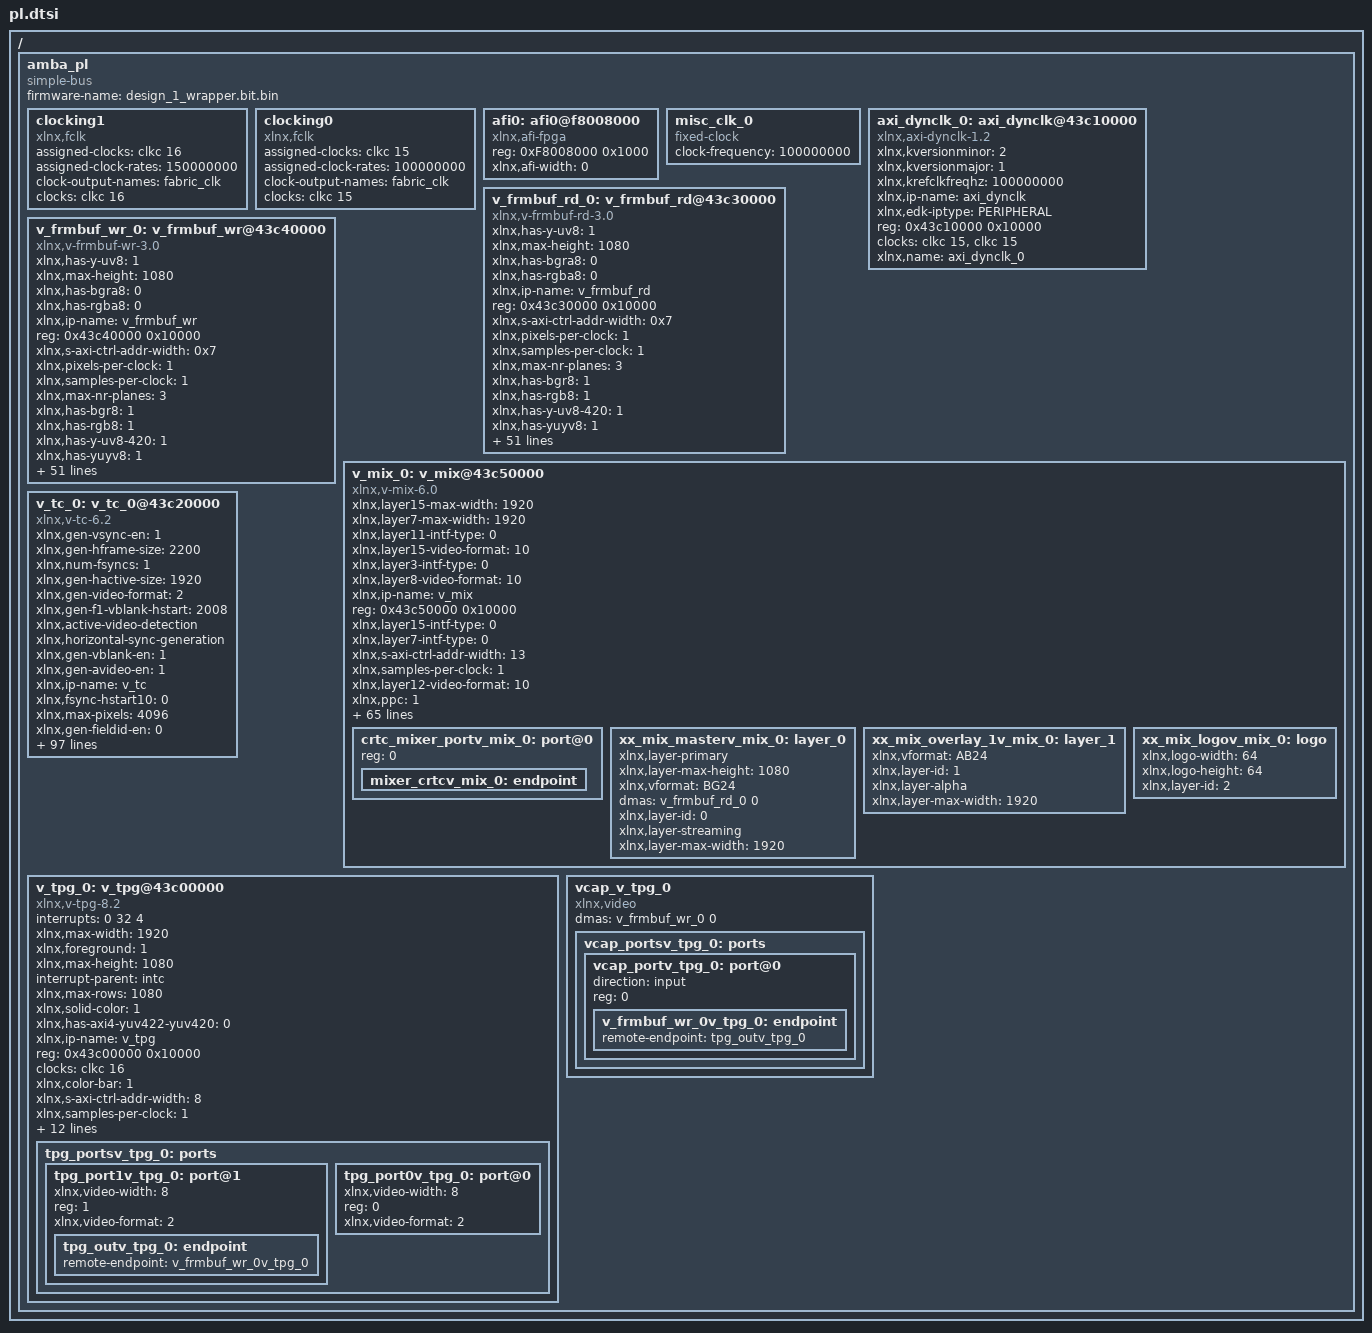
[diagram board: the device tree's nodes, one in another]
/ {
	amba_pl: amba_pl {
		ranges;
		compatible = "simple-bus";
		#address-cells = <1>;
		#size-cells = <1>;
		firmware-name = "design_1_wrapper.bit.bin";
		clocking1: clocking1 {
			compatible = "xlnx,fclk";
			assigned-clocks = <&clkc 16>;
			assigned-clock-rates = <150000000>;
			#clock-cells = <0>;
			clock-output-names = "fabric_clk";
			clocks = <&clkc 16>;
		};
		clocking0: clocking0 {
			compatible = "xlnx,fclk";
			assigned-clocks = <&clkc 15>;
			assigned-clock-rates = <100000000>;
			#clock-cells = <0>;
			clock-output-names = "fabric_clk";
			clocks = <&clkc 15>;
		};
		afi0: afi0@f8008000 {
			status = "okay";
			compatible = "xlnx,afi-fpga";
			#address-cells = <1>;
			reg = <0xF8008000 0x1000>;
			#size-cells = <0>;
			xlnx,afi-width = <0>;
		};
		misc_clk_0: misc_clk_0 {
			compatible = "fixed-clock";
			clock-frequency = <100000000>;
			#clock-cells = <0>;
		};
		axi_dynclk_0: axi_dynclk@43c10000 {
			xlnx,kversionminor = <2>;
			xlnx,kversionmajor = <1>;
			xlnx,krefclkfreqhz = <100000000>;
			compatible = "xlnx,axi-dynclk-1.2";
			status = "okay";
			clock-names = "REF_CLK_I" , "s_axi_lite_aclk";
			xlnx,ip-name = "axi_dynclk";
			xlnx,edk-iptype = "PERIPHERAL";
			reg = <0x43c10000 0x10000>;
			clocks = <&clkc 15>, <&clkc 15>;
			xlnx,name = "axi_dynclk_0";
		};
		v_frmbuf_rd_0: v_frmbuf_rd@43c30000 {
			xlnx,has-y-uv8 = <1>;
			xlnx,max-height = <1080>;
			xlnx,has-bgra8 = <0>;
			xlnx,has-rgba8 = <0>;
			xlnx,ip-name = "v_frmbuf_rd";
			reg = <0x43c30000 0x10000>;
			xlnx,s-axi-ctrl-addr-width = <0x7>;
			xlnx,pixels-per-clock = <1>;
			xlnx,samples-per-clock = <1>;
			xlnx,max-nr-planes = <3>;
			xlnx,has-bgr8 = <1>;
			xlnx,has-rgb8 = <1>;
			xlnx,has-y-uv8-420 = <1>;
			xlnx,has-yuyv8 = <1>;
			xlnx,has-y-u-v8 = <1>;
			interrupt-names = "interrupt";
			compatible = "xlnx,v-frmbuf-rd-3.0" , "xlnx,axi-frmbuf-rd-v2.2";
			xlnx,max-width = <1920>;
			xlnx,has-rgb16 = <0>;
			xlnx,vid-formats = "rgb888" , "xbgr8888" , "xrgb8888" , "bgr888" , "uyvy" , "y8" , "vuy888" , "xvuy8888" , "yuyv" , "nv12" , "nv16" , "y_u_v8";
			xlnx,has-bgrx8 = <1>;
			xlnx,has-rgbx8 = <1>;
			xlnx,has-rgbx10 = <0>;
			interrupt-parent = <&intc>;
			xlnx,aximm-num-outstanding = <4>;
			xlnx,has-uyvy8 = <1>;
			xlnx,use-uram = <0>;
			xlnx,has-rgbx12 = <0>;
			xlnx,aximm-burst-length = <16>;
			xlnx,aximm-addr-width = <32>;
			xlnx,video-width = <8>;
			xlnx,max-cols = <1920>;
			xlnx,has-yuv8 = <1>;
			status = "okay";
			xlnx,has-y-uv10-420 = <0>;
			xlnx,has-yuva8 = <0>;
			xlnx,has-y-uv12-420 = <0>;
			xlnx,name = "v_frmbuf_rd_0";
			interrupts = < 0 30 4 >;
			xlnx,has-y10 = <0>;
			xlnx,has-y-uv16-420 = <0>;
			xlnx,has-y12 = <0>;
			xlnx,has-alpha = <0>;
			xlnx,has-y-u-v10 = <0>;
			clocks = <&clkc 16>;
			xlnx,has-y16 = <0>;
			xlnx,dma-align = <8>;
			xlnx,has-y-u-v12 = <0>;
			xlnx,edk-iptype = "PERIPHERAL";
			xlnx,has-interlaced = <0>;
			xlnx,has-yuv16 = <0>;
			xlnx,has-yuvx8 = <1>;
			xlnx,is-tile-format = <0>;
			xlnx,dma-addr-width = <32>;
			clock-names = "ap_clk";
			xlnx,s-axi-ctrl-data-width = <0x20>;
			xlnx,has-y8 = <1>;
			xlnx,has-y-uv10 = <0>;
			xlnx,has-y-uv12 = <0>;
			xlnx,max-rows = <1080>;
			xlnx,has-yuvx10 = <0>;
			#dma-cells = <1>;
			xlnx,has-yuvx12 = <0>;
			xlnx,has-y-uv16 = <0>;
			xlnx,max-data-width = <8>;
			xlnx,has-y-u-v8-420 = <1>;
			xlnx,num-video-components = <3>;
			xlnx,aximm-data-width = <64>;
		};
		v_frmbuf_wr_0: v_frmbuf_wr@43c40000 {
			xlnx,has-y-uv8 = <1>;
			xlnx,max-height = <1080>;
			xlnx,has-bgra8 = <0>;
			xlnx,has-rgba8 = <0>;
			xlnx,ip-name = "v_frmbuf_wr";
			reg = <0x43c40000 0x10000>;
			xlnx,s-axi-ctrl-addr-width = <0x7>;
			xlnx,pixels-per-clock = <1>;
			xlnx,samples-per-clock = <1>;
			xlnx,max-nr-planes = <3>;
			xlnx,has-bgr8 = <1>;
			xlnx,has-rgb8 = <1>;
			xlnx,has-y-uv8-420 = <1>;
			xlnx,has-yuyv8 = <1>;
			xlnx,has-y-u-v8 = <1>;
			interrupt-names = "interrupt";
			compatible = "xlnx,v-frmbuf-wr-3.0" , "xlnx,axi-frmbuf-wr-v2.2";
			xlnx,max-width = <1920>;
			xlnx,has-rgb16 = <0>;
			xlnx,vid-formats = "rgb888" , "bgr888" , "xbgr8888" , "xrgb8888" , "uyvy" , "y8" , "vuy888" , "xvuy8888" , "yuyv" , "nv12" , "nv16" , "y_u_v8";
			xlnx,has-bgrx8 = <1>;
			xlnx,has-rgbx8 = <1>;
			xlnx,has-rgbx10 = <0>;
			interrupt-parent = <&intc>;
			xlnx,aximm-num-outstanding = <4>;
			xlnx,has-uyvy8 = <1>;
			xlnx,use-uram = <0>;
			xlnx,has-rgbx12 = <0>;
			xlnx,aximm-burst-length = <16>;
			xlnx,aximm-addr-width = <32>;
			xlnx,video-width = <8>;
			xlnx,max-cols = <1920>;
			xlnx,has-yuv8 = <1>;
			status = "okay";
			xlnx,has-y-uv10-420 = <0>;
			xlnx,has-yuva8 = <0>;
			xlnx,has-y-uv12-420 = <0>;
			xlnx,name = "v_frmbuf_wr_0";
			interrupts = < 0 31 4 >;
			xlnx,has-y10 = <0>;
			xlnx,has-y-uv16-420 = <0>;
			xlnx,has-y12 = <0>;
			xlnx,has-alpha = <0>;
			xlnx,has-y-u-v10 = <0>;
			clocks = <&clkc 16>;
			xlnx,has-y16 = <0>;
			xlnx,dma-align = <8>;
			xlnx,has-y-u-v12 = <0>;
			xlnx,edk-iptype = "PERIPHERAL";
			xlnx,has-interlaced = <0>;
			xlnx,has-yuv16 = <0>;
			xlnx,has-yuvx8 = <1>;
			xlnx,is-tile-format = <0>;
			xlnx,dma-addr-width = <32>;
			clock-names = "ap_clk";
			xlnx,s-axi-ctrl-data-width = <0x20>;
			xlnx,has-y8 = <1>;
			xlnx,has-y-uv10 = <0>;
			xlnx,has-y-uv12 = <0>;
			xlnx,max-rows = <1080>;
			xlnx,has-yuvx10 = <0>;
			#dma-cells = <1>;
			xlnx,has-yuvx12 = <0>;
			xlnx,has-y-uv16 = <0>;
			xlnx,max-data-width = <8>;
			xlnx,has-y-u-v8-420 = <1>;
			xlnx,num-video-components = <3>;
			xlnx,aximm-data-width = <64>;
		};
		v_mix_0: v_mix@43c50000 {
			xlnx,layer15-max-width = <1920>;
			xlnx,layer7-max-width = <1920>;
			xlnx,layer11-intf-type = <0>;
			xlnx,layer15-video-format = <10>;
			xlnx,layer3-intf-type = <0>;
			xlnx,layer8-video-format = <10>;
			xlnx,ip-name = "v_mix";
			reg = <0x43c50000 0x10000>;
			xlnx,layer15-intf-type = <0>;
			xlnx,layer7-intf-type = <0>;
			xlnx,s-axi-ctrl-addr-width = <13>;
			xlnx,samples-per-clock = <1>;
			xlnx,layer12-video-format = <10>;
			xlnx,ppc = <1>;
			xlnx,max-logo-rows = <64>;
			xlnx,layer5-video-format = <10>;
			interrupt-names = "interrupt";
			xlnx,layer12-max-width = <1920>;
			xlnx,layer2-video-format = <10>;
			xlnx,layer4-max-width = <1920>;
			compatible = "xlnx,v-mix-6.0" , "xlnx,mixer-3.0" , "xlnx,mixer-4.0" , "xlnx,v-mix-5.3" , "xlnx,mixer-5.0";
			xlnx,layer16-max-width = <1920>;
			xlnx,num-layers = <2>;
			xlnx,video-format = <0>;
			xlnx,layer8-max-width = <1920>;
			xlnx,layer12-intf-type = <0>;
			interrupt-parent = <&intc>;
			xlnx,aximm-num-outstanding = <4>;
			xlnx,layer4-intf-type = <0>;
			xlnx,aximm-burst-length = <16>;
			xlnx,aximm-addr-width = <32>;
			xlnx,layer16-intf-type = <0>;
			xlnx,layer1-alpha;
			xlnx,layer8-intf-type = <0>;
			xlnx,max-cols = <1920>;
			xlnx,layer14-video-format = <10>;
			xlnx,bpc = <8>;
			xlnx,nr-layers = <2>;
			xlnx,layer7-video-format = <10>;
			status = "okay";
			xlnx,layer1-max-width = <1920>;
			xlnx,use-uram-fifo = <0>;
			xlnx,name = "v_mix_0";
			xlnx,layer11-video-format = <10>;
			xlnx,layer13-max-width = <1920>;
			interrupts = < 0 33 4 >;
			xlnx,layer5-max-width = <1920>;
			xlnx,layer1-intf-type = <0>;
			xlnx,layer4-video-format = <10>;
			xlnx,layer9-max-width = <1920>;
			xlnx,layer13-intf-type = <0>;
			xlnx,layer5-intf-type = <0>;
			xlnx,layer1-video-format = <13>;
			clocks = <&clkc 16>;
			xlnx,use-uram-linebuf = <0>;
			xlnx,layer9-intf-type = <0>;
			xlnx,edk-iptype = "PERIPHERAL";
			xlnx,is-tile-format = <0>;
			xlnx,enable-csc-coefficient-registers = <0>;
			xlnx,layer10-max-width = <1920>;
			xlnx,layer16-video-format = <10>;
			xlnx,dma-addr-width = <32>;
			clock-names = "ap_clk";
			xlnx,layer2-max-width = <1920>;
			xlnx,layer9-video-format = <10>;
			xlnx,s-axi-ctrl-data-width = <32>;
			xlnx,max-logo-cols = <64>;
			xlnx,layer14-max-width = <1920>;
			xlnx,layer6-max-width = <1920>;
			xlnx,layer10-intf-type = <0>;
			xlnx,layer13-video-format = <10>;
			xlnx,layer2-intf-type = <0>;
			xlnx,layer6-video-format = <10>;
			xlnx,max-rows = <1080>;
			xlnx,layer14-intf-type = <0>;
			xlnx,layer6-intf-type = <0>;
			xlnx,layer10-video-format = <10>;
			xlnx,max-data-width = <8>;
			xlnx,layer3-video-format = <10>;
			xlnx,num-video-components = <3>;
			xlnx,layer11-max-width = <1920>;
			xlnx,aximm-data-width = <64>;
			xlnx,layer3-max-width = <1920>;
			crtc_mixer_portv_mix_0: port@0 {
				reg = <0>;
				mixer_crtcv_mix_0: endpoint {
				};
			};
			xx_mix_masterv_mix_0: layer_0 {
				xlnx,layer-primary;
				xlnx,layer-max-height = <1080>;
				xlnx,vformat = "BG24";
				dmas = <&v_frmbuf_rd_0 0>;
				xlnx,layer-id = <0>;
				xlnx,layer-streaming;
				dma-names = "dma0";
				xlnx,layer-max-width = <1920>;
			};
			xx_mix_overlay_1v_mix_0: layer_1 {
				xlnx,vformat = "AB24";
				xlnx,layer-id = <1>;
				xlnx,layer-alpha;
				xlnx,layer-max-width = <1920>;
			};
			xx_mix_logov_mix_0: logo {
				xlnx,logo-width = <64>;
				xlnx,logo-height = <64>;
				xlnx,layer-id = <2>;
			};
		};
		v_tc_0: v_tc_0@43c20000 {
			xlnx,gen-vsync-en = <1>;
			xlnx,gen-hframe-size = <2200>;
			xlnx,num-fsyncs = <1>;
			xlnx,gen-hactive-size = <1920>;
			xlnx,gen-video-format = <2>;
			xlnx,gen-f1-vblank-hstart = <2008>;
			xlnx,active-video-detection;
			xlnx,horizontal-sync-generation;
			xlnx,gen-vblank-en = <1>;
			xlnx,gen-avideo-en = <1>;
			xlnx,ip-name = "v_tc";
			xlnx,fsync-hstart10 = <0>;
			xlnx,max-pixels = <4096>;
			xlnx,gen-fieldid-en = <0>;
			reg = <0x43c20000 0x10000>;
			xlnx,det-vblank-en = <1>;
			xlnx,fsync-hstart11 = <0>;
			xlnx,fsync-hstart12 = <0>;
			xlnx,pixels-per-clock = <0x4>;
			xlnx,gen-interlaced = <0>;
			xlnx,det-avideo-en = <1>;
			xlnx,fsync-hstart13 = <0>;
			xlnx,fsync-hstart14 = <0>;
			xlnx,gen-f0-vblank-hend = <2008>;
			xlnx,fsync-hstart15 = <0>;
			xlnx,det-hsync-en = <1>;
			interrupt-names = "irq";
			xlnx,enable-generation;
			xlnx,gen-avideo-polarity = <1>;
			xlnx,max-lines-per-frame = <4096>;
			xlnx,has-axi4-lite = <1>;
			compatible = "xlnx,v-tc-6.2" , "xlnx,bridge-v-tc-6.1";
			xlnx,max-clocks-per-line = <4096>;
			xlnx,gen-f0-vframe-size = <1125>;
			xlnx,gen-f0-vblank-hstart = <2008>;
			interrupt-parent = <&intc>;
			xlnx,max-lines = <4096>;
			xlnx,gen-f0-vsync-vstart = <1083>;
			xlnx,horizontal-blank-generation;
			xlnx,gen-hsync-end = <2052>;
			xlnx,gen-f0-vsync-hstart = <2008>;
			xlnx,gen-f1-vsync-hend = <2008>;
			xlnx,vertical-blank-detection;
			xlnx,gen-vsync-polarity = <1>;
			xlnx,fsync-vstart0 = <0>;
			xlnx,gen-hsync-polarity = <1>;
			xlnx,fsync-vstart1 = <0>;
			status = "okay";
			xlnx,fsync-vstart2 = <0>;
			xlnx,gen-hsync-start = <2008>;
			xlnx,gen-f0-vsync-vend = <1088>;
			xlnx,fsync-vstart3 = <0>;
			xlnx,vertical-sync-detection;
			xlnx,frame-syncs = <1>;
			xlnx,fsync-vstart4 = <0>;
			xlnx,gen-vactive-size = <1080>;
			xlnx,name = "v_tc_0";
			xlnx,fsync-vstart5 = <0>;
			interrupts = < 0 29 4 >;
			xlnx,gen-achroma-en = <0>;
			xlnx,fsync-vstart6 = <0>;
			xlnx,det-fieldid-en = <0>;
			xlnx,fsync-vstart7 = <0>;
			xlnx,gen-hsync-en = <1>;
			xlnx,fsync-vstart8 = <0>;
			xlnx,fsync-vstart10 = <0>;
			xlnx,fsync-vstart9 = <0>;
			xlnx,fsync-vstart11 = <0>;
			xlnx,arbitrary-res-en = /bits/ 8 <0x0>;
			xlnx,fsync-vstart12 = <0>;
			xlnx,fsync-vstart13 = <0>;
			clocks = <&misc_clk_0>, <&clkc 15>;
			xlnx,fsync-vstart14 = <0>;
			xlnx,fsync-vstart15 = <0>;
			xlnx,gen-cparity = <0>;
			xlnx,edk-iptype = "PERIPHERAL";
			xlnx,vertical-sync-generation;
			xlnx,gen-f1-vblank-hend = <2008>;
			xlnx,det-vsync-en = <1>;
			xlnx,gen-vblank-polarity = <1>;
			xlnx,fsync-hstart0 = <0>;
			clock-names = "clk" , "s_axi_aclk";
			xlnx,interlace-en = <0>;
			xlnx,gen-auto-switch = <0>;
			xlnx,fsync-hstart1 = <0>;
			xlnx,fsync-hstart2 = <0>;
			xlnx,active-video-generation;
			xlnx,fsync-hstart3 = <0>;
			xlnx,fsync-hstart4 = <0>;
			xlnx,horizontal-blank-detection;
			xlnx,fsync-hstart5 = <0>;
			xlnx,gen-f1-vframe-size = <1125>;
			xlnx,fsync-hstart6 = <0>;
			xlnx,fsync-hstart7 = <0>;
			xlnx,fsync-hstart8 = <0>;
			xlnx,gen-hblank-en = <1>;
			xlnx,fsync-hstart9 = <0>;
			xlnx,horizontal-sync-detection;
			xlnx,gen-f1-vsync-vend = <1088>;
			xlnx,detect-en = <0>;
			xlnx,det-hblank-en = <1>;
			xlnx,vid-ppc = <4>;
			xlnx,has-intc-if = <0>;
			xlnx,generate-en = <1>;
			xlnx,gen-achroma-polarity = <1>;
			xlnx,sync-en = <0>;
			xlnx,det-achroma-en = <0>;
			xlnx,generator;
			xlnx,gen-f1-vsync-vstart = <1083>;
			xlnx,vertical-blank-generation;
			xlnx,gen-hblank-polarity = <1>;
			xlnx,video-mode = "1080p";
			xlnx,gen-fieldid-polarity = <1>;
			xlnx,gen-f1-vsync-hstart = <2008>;
			xlnx,gen-f0-vsync-hend = <2008>;
		};
		v_tpg_0: v_tpg@43c00000 {
			interrupts = < 0 32 4 >;
			compatible = "xlnx,v-tpg-8.2" , "xlnx,v-tpg-8.0";
			xlnx,max-width = <1920>;
			xlnx,foreground = <1>;
			xlnx,max-height = <1080>;
			interrupt-parent = <&intc>;
			xlnx,max-rows = <1080>;
			xlnx,solid-color = <1>;
			xlnx,has-axi4-yuv422-yuv420 = <0>;
			xlnx,ip-name = "v_tpg";
			reg = <0x43c00000 0x10000>;
			clocks = <&clkc 16>;
			xlnx,color-bar = <1>;
			xlnx,s-axi-ctrl-addr-width = <8>;
			xlnx,samples-per-clock = <1>;
			xlnx,max-data-width = <8>;
			xlnx,has-axi4s-slave = <0>;
			xlnx,ppc = <1>;
			xlnx,max-cols = <1920>;
			xlnx,edk-iptype = "PERIPHERAL";
			status = "okay";
			clock-names = "ap_clk";
			xlnx,zone-plate = <1>;
			xlnx,num-video-components = <3>;
			interrupt-names = "interrupt";
			xlnx,ramp = <1>;
			xlnx,color-sweep = <1>;
			xlnx,s-axi-ctrl-data-width = <32>;
			xlnx,display-port = <1>;
			xlnx,name = "v_tpg_0";
			tpg_portsv_tpg_0: ports {
				#address-cells = <1>;
				#size-cells = <0>;
				tpg_port1v_tpg_0: port@1 {
					xlnx,video-width = <8>;
					reg = <1>;
					xlnx,video-format = <2>;
					tpg_outv_tpg_0: endpoint {
						remote-endpoint = <&v_frmbuf_wr_0v_tpg_0>;
					};
				};
				tpg_port0v_tpg_0: port@0 {
					xlnx,video-width = <8>;
					reg = <0>;
					xlnx,video-format = <2>;
				};
			};
		};
		vcap_v_tpg_0 {
			compatible = "xlnx,video";
			dmas = <&v_frmbuf_wr_0 0>;
			dma-names = "port0";
			vcap_portsv_tpg_0: ports {
				#address-cells = <1>;
				#size-cells = <0>;
				vcap_portv_tpg_0: port@0 {
					direction = "input";
					reg = <0>;
					v_frmbuf_wr_0v_tpg_0: endpoint {
						remote-endpoint = <&tpg_outv_tpg_0>;
					};
				};
			};
		};
	};
};
